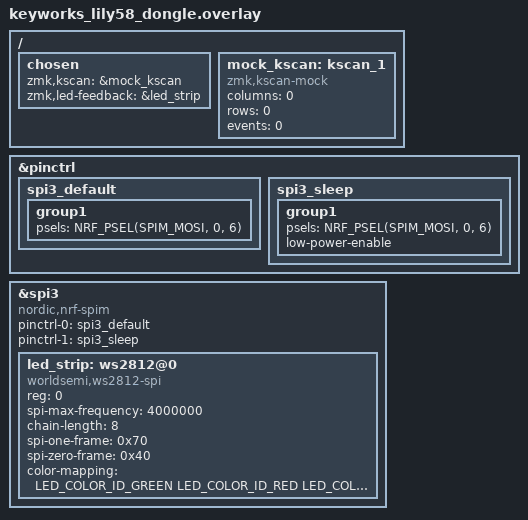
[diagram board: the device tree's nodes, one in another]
/*
 * Copyright (c) 2022 The ZMK Contributors
 *
 * SPDX-License-Identifier: MIT
 */

#include <dt-bindings/led/led.h>

#include "keyworks_lily58_layout.dtsi"
#include "keyworks_lily58_sensors.dtsi"

/ {
    chosen {
        zmk,kscan = &mock_kscan;
        zmk,led-feedback = &led_strip;
    };

    // The dongle has no switches, the keys are sent by the two halves.
    mock_kscan: kscan_1 {
        compatible = "zmk,kscan-mock";
        columns = <0>;
        rows = <0>;
        events = <0>;
    };
};

// WS2812 data line on P0.06 (pro_micro pin 1) through the SPI MOSI pin
&pinctrl {
    spi3_default: spi3_default {
        group1 {
            psels = <NRF_PSEL(SPIM_MOSI, 0, 6)>;
        };
    };

    spi3_sleep: spi3_sleep {
        group1 {
            psels = <NRF_PSEL(SPIM_MOSI, 0, 6)>;
            low-power-enable;
        };
    };
};

&spi3 {
    compatible = "nordic,nrf-spim";
    status = "okay";
    pinctrl-0 = <&spi3_default>;
    pinctrl-1 = <&spi3_sleep>;
    pinctrl-names = "default", "sleep";

    led_strip: ws2812@0 {
        compatible = "worldsemi,ws2812-spi";
        reg = <0>;
        spi-max-frequency = <4000000>;
        chain-length = <8>;
        spi-one-frame = <0x70>;
        spi-zero-frame = <0x40>;
        color-mapping = <LED_COLOR_ID_GREEN LED_COLOR_ID_RED LED_COLOR_ID_BLUE>;
    };
};
